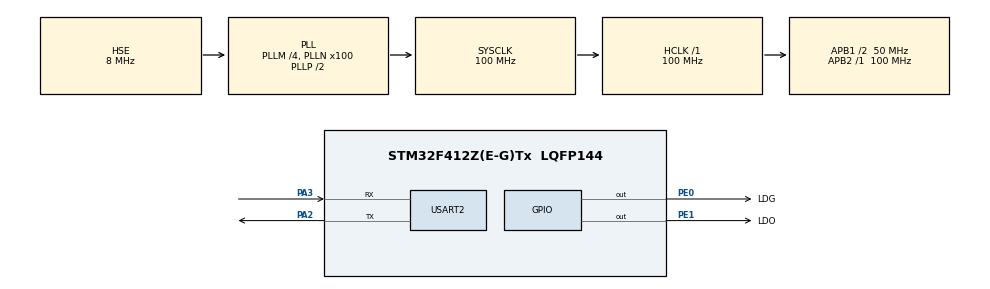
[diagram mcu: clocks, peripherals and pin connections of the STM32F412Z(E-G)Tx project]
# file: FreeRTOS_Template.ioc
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Mcu.Family=STM32F4
Mcu.Name=STM32F412Z(E-G)Tx
Mcu.Package=LQFP144
NVIC.PriorityGroup=NVIC_PRIORITYGROUP_4
NVIC.TIM8_TRG_COM_TIM14_IRQn=true\:15\:0\:false\:false\:true\:false\:true\:true
NVIC.TimeBase=TIM8_TRG_COM_TIM14_IRQn
NVIC.TimeBaseIP=TIM14
PA2.Mode=Asynchronous
PA2.Signal=USART2_TX
PA3.Mode=Asynchronous
PA3.Signal=USART2_RX
PE0.GPIO_Label=LDG
PE0.Signal=GPIO_Output
PE1.GPIO_Label=LDO
PE1.Signal=GPIO_Output
PH0\ -\ OSC_IN.Mode=HSE-External-Clock-Source
PH0\ -\ OSC_IN.Signal=RCC_OSC_IN
PH1\ -\ OSC_OUT.Mode=HSE-External-Clock-Source
PH1\ -\ OSC_OUT.Signal=RCC_OSC_OUT
ProjectManager.HeapSize=0x200
ProjectManager.StackSize=0x400
ProjectManager.TargetToolchain=STM32CubeIDE
RCC.AHBFreq_Value=100000000
RCC.APB1CLKDivider=RCC_HCLK_DIV2
RCC.APB1Freq_Value=50000000
RCC.APB1TimFreq_Value=100000000
RCC.APB2Freq_Value=100000000
RCC.APB2TimFreq_Value=100000000
RCC.CortexFreq_Value=100000000
RCC.HCLKFreq_Value=100000000
RCC.HSE_VALUE=8000000
RCC.PLLM=4
RCC.PLLN=100
RCC.PLLSourceVirtual=RCC_PLLSOURCE_HSE
RCC.SYSCLKFreq_VALUE=100000000
RCC.SYSCLKSource=RCC_SYSCLKSOURCE_PLLCLK
RCC.USBFreq_Value=100000000
RCC.VCOOutputFreq_Value=200000000
USART2.VirtualMode=VM_ASYNC
VP_SYS_VS_tim14.Mode=TIM14
board=custom

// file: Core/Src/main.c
/* USER CODE BEGIN Header */
/**
 ******************************************************************************
 * @file           : main.c
 * @brief          : Main program body
 ******************************************************************************
 * @attention
 *
 * Copyright (c) 2023 STMicroelectronics.
 * All rights reserved.
 *
 * This software is licensed under terms that can be found in the LICENSE file
 * in the root directory of this software component.
 * If no LICENSE file comes with this software, it is provided AS-IS.
 *
 ******************************************************************************
 */
/* USER CODE END Header */
#include "main.h"

/* USER CODE BEGIN Includes */
#include "SEGGER_SYSVIEW_FreeRTOS.h"

/* USER CODE END Includes */

/* USER CODE BEGIN PTD */
void my_main(void);

/* USER CODE END PTD */

UART_HandleTypeDef huart2;

void SystemClock_Config(void);
static void MX_GPIO_Init(void);
static void MX_USART2_UART_Init(void);

int main(void)
{

  /* MCU Configuration--------------------------------------------------------*/

  /* Reset of all peripherals, Initializes the Flash interface and the Systick. */
  HAL_Init();

  /* Configure the system clock */
  SystemClock_Config();

  /* Initialize all configured peripherals */
  MX_GPIO_Init();
  MX_USART2_UART_Init();
  /* USER CODE BEGIN 2 */

	my_main();
  /* USER CODE END 2 */

  /* Infinite loop */
	while (1) {

	}
}

void SystemClock_Config(void)
{
  RCC_OscInitTypeDef RCC_OscInitStruct = {0};
  RCC_ClkInitTypeDef RCC_ClkInitStruct = {0};

  /** Configure the main internal regulator output voltage
  */
  __HAL_RCC_PWR_CLK_ENABLE();
  __HAL_PWR_VOLTAGESCALING_CONFIG(PWR_REGULATOR_VOLTAGE_SCALE1);

  /** Initializes the RCC Oscillators according to the specified parameters
  * in the RCC_OscInitTypeDef structure.
  */
  RCC_OscInitStruct.OscillatorType = RCC_OSCILLATORTYPE_HSE;
  RCC_OscInitStruct.HSEState = RCC_HSE_BYPASS;
  RCC_OscInitStruct.PLL.PLLState = RCC_PLL_ON;
  RCC_OscInitStruct.PLL.PLLSource = RCC_PLLSOURCE_HSE;
  RCC_OscInitStruct.PLL.PLLM = 4;
  RCC_OscInitStruct.PLL.PLLN = 100;
  RCC_OscInitStruct.PLL.PLLP = RCC_PLLP_DIV2;
  RCC_OscInitStruct.PLL.PLLQ = 2;
  RCC_OscInitStruct.PLL.PLLR = 2;
  if (HAL_RCC_OscConfig(&RCC_OscInitStruct) != HAL_OK)
  {
    Error_Handler();
  }

  /** Initializes the CPU, AHB and APB buses clocks
  */
  RCC_ClkInitStruct.ClockType = RCC_CLOCKTYPE_HCLK|RCC_CLOCKTYPE_SYSCLK
                              |RCC_CLOCKTYPE_PCLK1|RCC_CLOCKTYPE_PCLK2;
  RCC_ClkInitStruct.SYSCLKSource = RCC_SYSCLKSOURCE_PLLCLK;
  RCC_ClkInitStruct.AHBCLKDivider = RCC_SYSCLK_DIV1;
  RCC_ClkInitStruct.APB1CLKDivider = RCC_HCLK_DIV2;
  RCC_ClkInitStruct.APB2CLKDivider = RCC_HCLK_DIV1;

  if (HAL_RCC_ClockConfig(&RCC_ClkInitStruct, FLASH_LATENCY_3) != HAL_OK)
  {
    Error_Handler();
  }
}

static void MX_USART2_UART_Init(void)
{

  huart2.Instance = USART2;
  huart2.Init.BaudRate = 115200;
  huart2.Init.WordLength = UART_WORDLENGTH_8B;
  huart2.Init.StopBits = UART_STOPBITS_1;
  huart2.Init.Parity = UART_PARITY_NONE;
  huart2.Init.Mode = UART_MODE_TX_RX;
  huart2.Init.HwFlowCtl = UART_HWCONTROL_NONE;
  huart2.Init.OverSampling = UART_OVERSAMPLING_16;
  if (HAL_UART_Init(&huart2) != HAL_OK)
  {
    Error_Handler();
  }

}

static void MX_GPIO_Init(void)
{
  GPIO_InitTypeDef GPIO_InitStruct = {0};

  /* GPIO Ports Clock Enable */
  __HAL_RCC_GPIOH_CLK_ENABLE();
  __HAL_RCC_GPIOA_CLK_ENABLE();
  __HAL_RCC_GPIOE_CLK_ENABLE();

  /*Configure GPIO pin Output Level */
  HAL_GPIO_WritePin(GPIOE, LDG_Pin|LDO_Pin, GPIO_PIN_RESET);

  /*Configure GPIO pins : LDG_Pin LDO_Pin */
  GPIO_InitStruct.Pin = LDG_Pin|LDO_Pin;
  GPIO_InitStruct.Mode = GPIO_MODE_OUTPUT_PP;
  GPIO_InitStruct.Pull = GPIO_NOPULL;
  GPIO_InitStruct.Speed = GPIO_SPEED_FREQ_LOW;
  HAL_GPIO_Init(GPIOE, &GPIO_InitStruct);

}

/* USER CODE BEGIN 4 */
void vApplicationIdleHook() {
	// Send  CPU to normal sleep (Wait For Interrupt)
	__WFI();

}
/* USER CODE END 4 */

void HAL_TIM_PeriodElapsedCallback(TIM_HandleTypeDef *htim)
{
  /* USER CODE BEGIN Callback 0 */
traceISR_ENTER();
  /* USER CODE END Callback 0 */
  if (htim->Instance == TIM9) {
    HAL_IncTick();
  }
  /* USER CODE BEGIN Callback 1 */
traceISR_EXIT();
  /* USER CODE END Callback 1 */
}

void Error_Handler(void)
{
	__disable_irq();
	while (1) {
	}
}
